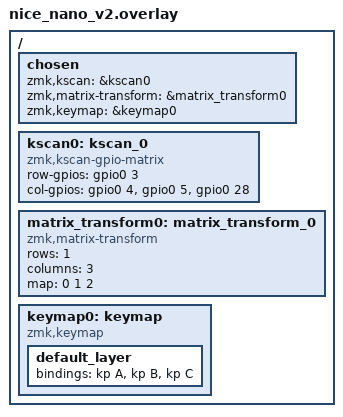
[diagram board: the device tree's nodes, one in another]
#include <dt-bindings/zmk/matrix_transform.h>

/ {
    chosen {
        zmk,kscan = &kscan0;
        zmk,matrix-transform = &matrix_transform0;
        zmk,keymap = &keymap0;
    };

    kscan0: kscan_0 {
        compatible = "zmk,kscan-gpio-matrix";
        row-gpios = <&gpio0 3 (GPIO_ACTIVE_HIGH | GPIO_PULL_UP)>;
        col-gpios = <&gpio0 4 (GPIO_ACTIVE_HIGH | GPIO_PULL_DOWN)>,
                    <&gpio0 5 (GPIO_ACTIVE_HIGH | GPIO_PULL_DOWN)>,
                    <&gpio0 28 (GPIO_ACTIVE_HIGH | GPIO_PULL_DOWN)>;
    };

    matrix_transform0: matrix_transform_0 {
        compatible = "zmk,matrix-transform";
        rows = <1>;
        columns = <3>;
        map = <0 1 2>;
    };

    keymap0: keymap {
        compatible = "zmk,keymap";
        default_layer {
            bindings = <
                &kp A &kp B &kp C
            >;
        };
    };
};
